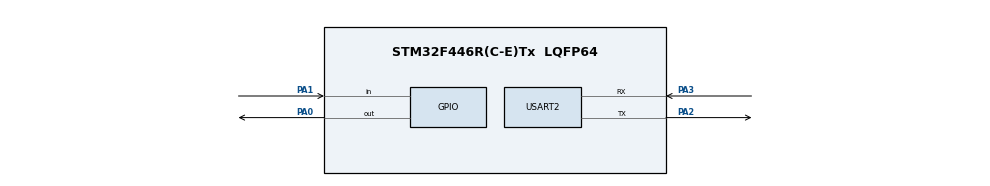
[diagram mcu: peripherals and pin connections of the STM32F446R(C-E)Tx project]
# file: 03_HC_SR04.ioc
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Mcu.Family=STM32F4
Mcu.Name=STM32F446R(C-E)Tx
Mcu.Package=LQFP64
NVIC.PriorityGroup=NVIC_PRIORITYGROUP_4
PA0-WKUP.Signal=GPIO_Output
PA1.Signal=GPIO_Input
PA2.Mode=Asynchronous
PA2.Signal=USART2_TX
PA3.Mode=Asynchronous
PA3.Signal=USART2_RX
ProjectManager.HeapSize=0x200
ProjectManager.StackSize=0x400
ProjectManager.TargetToolchain=STM32CubeIDE
RCC.CortexFreq_Value=16000000
RCC.USBFreq_Value=96000000
RCC.VCOOutputFreq_Value=192000000
TIM2.Prescaler=15
USART2.VirtualMode=VM_ASYNC
VP_TIM2_VS_ClockSourceINT.Mode=Internal
board=custom

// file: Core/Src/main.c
/* USER CODE BEGIN Header */
/**
  ******************************************************************************
  * @file           : main.c
  * @brief          : Main program body
  ******************************************************************************
  * @attention
  *
  * Copyright (c) 2026 STMicroelectronics.
  * All rights reserved.
  *
  * This software is licensed under terms that can be found in the LICENSE file
  * in the root directory of this software component.
  * If no LICENSE file comes with this software, it is provided AS-IS.
  *
  ******************************************************************************
  */
/* USER CODE END Header */
#include "main.h"

/* USER CODE BEGIN Includes */
#include <stdio.h>
/* USER CODE END Includes */

TIM_HandleTypeDef htim2;

UART_HandleTypeDef huart2;

/* USER CODE BEGIN PV */
uint32_t echoTime;
uint32_t distance;
/* USER CODE END PV */

void SystemClock_Config(void);
static void MX_GPIO_Init(void);
static void MX_TIM2_Init(void);
static void MX_USART2_UART_Init(void);

/* USER CODE BEGIN 0 */
int __io_putchar(int ch)
{
	HAL_UART_Transmit(&huart2, (uint8_t *)&ch, 1, HAL_MAX_DELAY);
	return ch;
}

void delay_us(uint16_t us)
{
	__HAL_TIM_SET_COUNTER(&htim2, 0);

	while(__HAL_TIM_GET_COUNTER(&htim2) < us)
	{
	}

}
/* USER CODE END 0 */

int main(void)
{

  /* MCU Configuration--------------------------------------------------------*/

  /* Reset of all peripherals, Initializes the Flash interface and the Systick. */
  HAL_Init();

  /* Configure the system clock */
  SystemClock_Config();

  /* Initialize all configured peripherals */
  MX_GPIO_Init();
  MX_TIM2_Init();
  MX_USART2_UART_Init();
  /* USER CODE BEGIN 2 */
HAL_TIM_Base_Start(&htim2);

printf("\r\n=== HC-SR04 START ===\r\n");
  /* USER CODE END 2 */

  /* Infinite loop */
  while (1)
  {
	  HAL_GPIO_WritePin(GPIOA, GPIO_PIN_0, GPIO_PIN_RESET);
	  delay_us(2);

	  HAL_GPIO_WritePin(GPIOA, GPIO_PIN_0, GPIO_PIN_SET);
	  delay_us(10);

	  HAL_GPIO_WritePin(GPIOA, GPIO_PIN_0, GPIO_PIN_RESET);

	  printf("TRIG sent\r\n");

	  /* ECHO가 HIGH 될 때까지 기다림 */
	  while (HAL_GPIO_ReadPin(GPIOA, GPIO_PIN_1) == GPIO_PIN_RESET)
	  {
	  }

	  printf("ECHO HIGH\r\n");

	  /* HIGH가 시작됐으니까 Timer 0부터 측정 */
	  __HAL_TIM_SET_COUNTER(&htim2, 0);

	  /* ECHO가 LOW 될 때까지 기다림 */
	  while (HAL_GPIO_ReadPin(GPIOA, GPIO_PIN_1) == GPIO_PIN_SET)
	  {
	  }

	  /* HIGH가 유지된 시간 */
	  echoTime = __HAL_TIM_GET_COUNTER(&htim2);

	  /* 거리 계산 */
	  distance = echoTime / 58;

	  /* UART 출력 */
	  printf("Distance = %lu cm\r\n", distance);

	  HAL_Delay(500);
  }
}

void SystemClock_Config(void)
{
  RCC_OscInitTypeDef RCC_OscInitStruct = {0};
  RCC_ClkInitTypeDef RCC_ClkInitStruct = {0};

  /** Configure the main internal regulator output voltage
  */
  __HAL_RCC_PWR_CLK_ENABLE();
  __HAL_PWR_VOLTAGESCALING_CONFIG(PWR_REGULATOR_VOLTAGE_SCALE3);

  /** Initializes the RCC Oscillators according to the specified parameters
  * in the RCC_OscInitTypeDef structure.
  */
  RCC_OscInitStruct.OscillatorType = RCC_OSCILLATORTYPE_HSI;
  RCC_OscInitStruct.HSIState = RCC_HSI_ON;
  RCC_OscInitStruct.HSICalibrationValue = RCC_HSICALIBRATION_DEFAULT;
  RCC_OscInitStruct.PLL.PLLState = RCC_PLL_NONE;
  if (HAL_RCC_OscConfig(&RCC_OscInitStruct) != HAL_OK)
  {
    Error_Handler();
  }

  /** Initializes the CPU, AHB and APB buses clocks
  */
  RCC_ClkInitStruct.ClockType = RCC_CLOCKTYPE_HCLK|RCC_CLOCKTYPE_SYSCLK
                              |RCC_CLOCKTYPE_PCLK1|RCC_CLOCKTYPE_PCLK2;
  RCC_ClkInitStruct.SYSCLKSource = RCC_SYSCLKSOURCE_HSI;
  RCC_ClkInitStruct.AHBCLKDivider = RCC_SYSCLK_DIV1;
  RCC_ClkInitStruct.APB1CLKDivider = RCC_HCLK_DIV1;
  RCC_ClkInitStruct.APB2CLKDivider = RCC_HCLK_DIV1;

  if (HAL_RCC_ClockConfig(&RCC_ClkInitStruct, FLASH_LATENCY_0) != HAL_OK)
  {
    Error_Handler();
  }
}

static void MX_TIM2_Init(void)
{

  TIM_ClockConfigTypeDef sClockSourceConfig = {0};
  TIM_MasterConfigTypeDef sMasterConfig = {0};

  htim2.Instance = TIM2;
  htim2.Init.Prescaler = 15;
  htim2.Init.CounterMode = TIM_COUNTERMODE_UP;
  htim2.Init.Period = 4294967295;
  htim2.Init.ClockDivision = TIM_CLOCKDIVISION_DIV1;
  htim2.Init.AutoReloadPreload = TIM_AUTORELOAD_PRELOAD_DISABLE;
  if (HAL_TIM_Base_Init(&htim2) != HAL_OK)
  {
    Error_Handler();
  }
  sClockSourceConfig.ClockSource = TIM_CLOCKSOURCE_INTERNAL;
  if (HAL_TIM_ConfigClockSource(&htim2, &sClockSourceConfig) != HAL_OK)
  {
    Error_Handler();
  }
  sMasterConfig.MasterOutputTrigger = TIM_TRGO_RESET;
  sMasterConfig.MasterSlaveMode = TIM_MASTERSLAVEMODE_DISABLE;
  if (HAL_TIMEx_MasterConfigSynchronization(&htim2, &sMasterConfig) != HAL_OK)
  {
    Error_Handler();
  }

}

static void MX_USART2_UART_Init(void)
{

  huart2.Instance = USART2;
  huart2.Init.BaudRate = 115200;
  huart2.Init.WordLength = UART_WORDLENGTH_8B;
  huart2.Init.StopBits = UART_STOPBITS_1;
  huart2.Init.Parity = UART_PARITY_NONE;
  huart2.Init.Mode = UART_MODE_TX_RX;
  huart2.Init.HwFlowCtl = UART_HWCONTROL_NONE;
  huart2.Init.OverSampling = UART_OVERSAMPLING_16;
  if (HAL_UART_Init(&huart2) != HAL_OK)
  {
    Error_Handler();
  }

}

static void MX_GPIO_Init(void)
{
  GPIO_InitTypeDef GPIO_InitStruct = {0};

  /* GPIO Ports Clock Enable */
  __HAL_RCC_GPIOA_CLK_ENABLE();

  /*Configure GPIO pin Output Level */
  HAL_GPIO_WritePin(GPIOA, GPIO_PIN_0, GPIO_PIN_RESET);

  /*Configure GPIO pin : PA0 */
  GPIO_InitStruct.Pin = GPIO_PIN_0;
  GPIO_InitStruct.Mode = GPIO_MODE_OUTPUT_PP;
  GPIO_InitStruct.Pull = GPIO_NOPULL;
  GPIO_InitStruct.Speed = GPIO_SPEED_FREQ_LOW;
  HAL_GPIO_Init(GPIOA, &GPIO_InitStruct);

  /*Configure GPIO pin : PA1 */
  GPIO_InitStruct.Pin = GPIO_PIN_1;
  GPIO_InitStruct.Mode = GPIO_MODE_INPUT;
  GPIO_InitStruct.Pull = GPIO_NOPULL;
  HAL_GPIO_Init(GPIOA, &GPIO_InitStruct);

}

void Error_Handler(void)
{
  __disable_irq();
  while (1)
  {
  }
}
